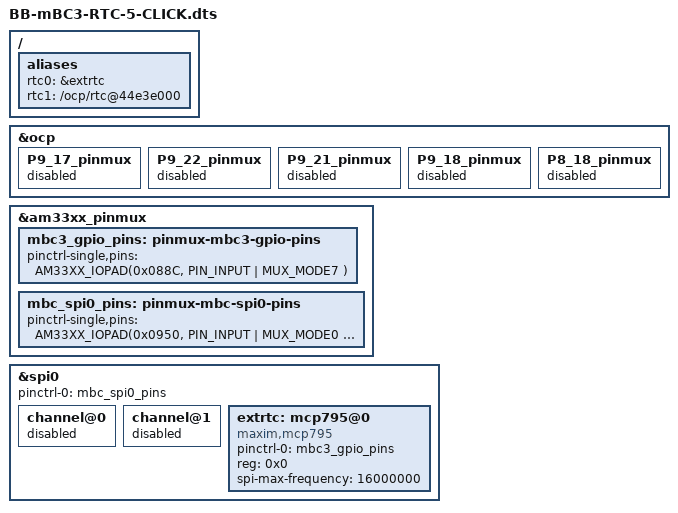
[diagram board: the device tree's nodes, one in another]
/*
 * Copyright (C) 2018 Robert Nelson <robertcnelson@gmail.com>
 *
 * This program is free software; you can redistribute it and/or modify
 * it under the terms of the GNU General Public License version 2 as
 * published by the Free Software Foundation.
 *
 * https://www.mikroe.com/rtc-5-click
 * https://download.mikroe.com/documents/add-on-boards/click/rtc-5/rtc-5-click-manual-v100.pdf
 *
 * Make sure to change the J7/J8 Jumpers to SPI Mode...
 */

/dts-v1/;
/plugin/;

#include <dt-bindings/gpio/gpio.h>
#include <dt-bindings/pinctrl/am33xx.h>
#include <dt-bindings/interrupt-controller/irq.h>

/ {
	/*
	 * Free up the pins used by the cape from the pinmux helpers.
	 */
	fragment@0 {
		target = <&ocp>;
		__overlay__ {
			//P8_14_pinmux { status = "disabled"; };	/* RESET - gpio0[26] */

			/* Click 3 */
			P9_17_pinmux { status = "disabled"; };	/* CS - spi0_cs0 */

			P9_22_pinmux { status = "disabled"; };	/* SCK - spi0_sclk */
			P9_21_pinmux { status = "disabled"; };	/* MISO - spi0_d0 */
			P9_18_pinmux { status = "disabled"; };	/* MOSI - spi0_d1 */

			// P8_19_pinmux { status = "disabled"; };	/* PWM - ehrpwm2a */
			P8_18_pinmux { status = "disabled"; };	/* MFP - gpio2[1] */

			//P9_26_pinmux { status = "disabled"; };	/* RX - uart1_rxd */
			//P9_24_pinmux { status = "disabled"; };	/* TX - uart1_txd */
			//P9_19_pinmux { status = "disabled"; };	/* SCL */
			//P9_20_pinmux { status = "disabled"; };	/* SDA */
		};
	};

	fragment@1 {
		target-path="/";
		__overlay__ {
			aliases {
				rtc0 = &extrtc;
				rtc1 = "/ocp/rtc@44e3e000";
			};
		};
	};

	fragment@2 {
		target = <&am33xx_pinmux>;
		__overlay__ {
			mbc3_gpio_pins: pinmux-mbc3-gpio-pins {
				pinctrl-single,pins = <
					AM33XX_IOPAD(0x088C, PIN_INPUT | MUX_MODE7 ) /* P8_18 (V12) gpmc_clk.gpio2[1] MFP */
					//AM33XX_IOPAD(0x0828, PIN_INPUT | MUX_MODE7 ) /* P8_14 (T11) gpmc_ad10.gpio0[26] RESET */
				>;
			};

			mbc_spi0_pins: pinmux-mbc-spi0-pins {
				pinctrl-single,pins = <
					AM33XX_IOPAD(0x0950, PIN_INPUT | MUX_MODE0 ) /* P9_22 (A17) spi0_sclk.spi0_sclk */
					AM33XX_IOPAD(0x0954, PIN_INPUT | MUX_MODE0 ) /* P9_21 (B17) spi0_d0.spi0_d0 */
					AM33XX_IOPAD(0x0958, PIN_INPUT | MUX_MODE0 ) /* P9_18 (B16) spi0_d1.spi0_d1 */

					/* Click 3 */
					AM33XX_IOPAD(0x095c, PIN_INPUT | MUX_MODE0 ) /* P9_17 (A16) spi0_cs0.spi0_cs0 */
				>;
			};
		};
	};

	fragment@3 {
		target = <&spi0>;
		__overlay__ {
			status = "okay";
			pinctrl-names = "default";
			pinctrl-0 = <&mbc_spi0_pins>;

			channel@0{ status = "disabled"; };
			channel@1{ status = "disabled"; };
		};
	};

	fragment@4 {
		target = <&spi0>;
		__overlay__ {
			#address-cells = <1>;
			#size-cells = <0>;

			extrtc: mcp795@0 {
				compatible = "maxim,mcp795";
				pinctrl-names = "default";
				pinctrl-0 = <&mbc3_gpio_pins>;
				reg = <0x0>;
				spi-max-frequency = <16000000>;
			};
		};
	};
};
